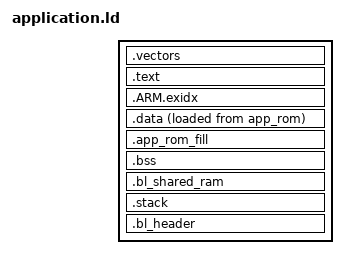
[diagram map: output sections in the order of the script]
INCLUDE memory.ld

SECTIONS
{
    /*
     * The linker moves the .vectors section into itcm when itcm is
     * enabled via the -mitcm option, but only when this .vectors output
     * section exists in the linker script.
     */
    .vectors :
    {
        . = ALIGN(4);
        __approm_start = .;
        _sfixed = .;
        KEEP(*(.vectors .vectors.* .vectors_default .vectors_default.*))
        KEEP(*(.isr_vector))
        KEEP(*(.reset*))
        KEEP(*(.after_vectors))
    } > app_rom
    /*
     * Code Sections - Note that standard input sections such as
     * *(.text), *(.text.*), *(.rodata), & *(.rodata.*)
     * are not mapped here. The best-fit allocator locates them,
     * so that input sections may flow around absolute sections
     * as needed.
     */
    .text :
    {
        . = ALIGN(4);
        *(.glue_7t) *(.glue_7)
        *(.gnu.linkonce.r.*)
        *(.ARM.extab* .gnu.linkonce.armextab.*)

        /* Support C constructors, and C destructors in both user code
           and the C library. This also provides support for C++ code. */
        . = ALIGN(4);
        KEEP(*(.init))
        . = ALIGN(4);
        __preinit_array_start = .;
        KEEP (*(.preinit_array))
        __preinit_array_end = .;

        . = ALIGN(4);
        __init_array_start = .;
        KEEP (*(SORT(.init_array.*)))
        KEEP (*(.init_array))
        __init_array_end = .;

        . = ALIGN(0x4);
        KEEP (*crtbegin.o(.ctors))
        KEEP (*(EXCLUDE_FILE (*crtend.o) .ctors))
        KEEP (*(SORT(.ctors.*)))
        KEEP (*crtend.o(.ctors))

        . = ALIGN(4);
        KEEP(*(.fini))

        . = ALIGN(4);
        __fini_array_start = .;
        KEEP (*(.fini_array))
        KEEP (*(SORT(.fini_array.*)))
        __fini_array_end = .;

        KEEP (*crtbegin.o(.dtors))
        KEEP (*(EXCLUDE_FILE (*crtend.o) .dtors))
        KEEP (*(SORT(.dtors.*)))
        KEEP (*crtend.o(.dtors))

        . = ALIGN(4);
        _efixed = .;            /* End of text section */
    } > app_rom

    /* .ARM.exidx is sorted, so has to go in its own output section.  */
    PROVIDE_HIDDEN (__exidx_start = .);
    .ARM.exidx :
    {
      *(.ARM.exidx* .gnu.linkonce.armexidx.*)
    } > app_rom
    PROVIDE_HIDDEN (__exidx_end = .);

    . = ALIGN(4);
    __etext = .;

    .data :
	{
		__data_start__ = .;
		*(vtable)
		*(.data*)

		. = ALIGN(4);
		/* preinit data */
		PROVIDE_HIDDEN (__preinit_array_start = .);
		KEEP(*(.preinit_array))
		PROVIDE_HIDDEN (__preinit_array_end = .);

		. = ALIGN(4);
		/* init data */
		PROVIDE_HIDDEN (__init_array_start = .);
		KEEP(*(SORT(.init_array.*)))
		KEEP(*(.init_array))
		PROVIDE_HIDDEN (__init_array_end = .);


		. = ALIGN(4);
		/* finit data */
		PROVIDE_HIDDEN (__fini_array_start = .);
		KEEP(*(SORT(.fini_array.*)))
		KEEP(*(.fini_array))
		PROVIDE_HIDDEN (__fini_array_end = .);

		KEEP(*(.jcr*))
		. = ALIGN(16);
		/* All data end */
		__data_end__ = .;
        _data_sizeof = SIZEOF(.data);
	} > ram AT > app_rom

    .app_rom_fill : {
        FILL(0xFFFFFFFF);
        . = ORIGIN(app_rom) + LENGTH(app_rom) - 4;
        __approm_end = .;
        LONG(0xFFFFFFFF)
    } > app_rom

    /*
     *  Align here to ensure that the .bss section occupies space up to
     *  _end.  Align after .bss to ensure correct alignment even if the
     *  .bss section disappears because there are no input sections.
     *
     *  Note that input sections named .bss* are no longer mapped here.
     *  The best-fit allocator locates them, so that they may flow
     *  around absolute sections as needed.
     */
    .bss :
	{
		. = ALIGN(4);
		__bss_start__ = .;
		*(.bss*)
		*(COMMON)
		. = ALIGN(4);
		__bss_end__ = .;
	} > ram

    .bl_shared_ram (NOLOAD) :
    {
        . = ALIGN(4);
        *(.bl_shared_ram*)
        . = ALIGN(4);
    } > bl_shared_ram

    /* stack section */
    .stack (NOLOAD):
    {
        . = ALIGN(8);
        _sstack = .;
        . = . + STACK_SIZE;
        . = ALIGN(8);
        _estack = .;
    } > ram

    . = ALIGN(4);
    _end = . ;
    _ram_end_ = ORIGIN(ram) + LENGTH(ram) -1 ;

    .bl_header : {
        . = ALIGN(4);
        __bootheader_start = .;
        KEEP(*(.bl_header.data));
        FILL(0xFFFFFFFF);
        . = ORIGIN(bl_header) + LENGTH(bl_header) - 4;      /* Note shorter to accommodate following LONG */
        __bootheader_end = .;
        KEEP(*(.bl_header.crc));
        . = ALIGN(4);
    } > bl_header
}
